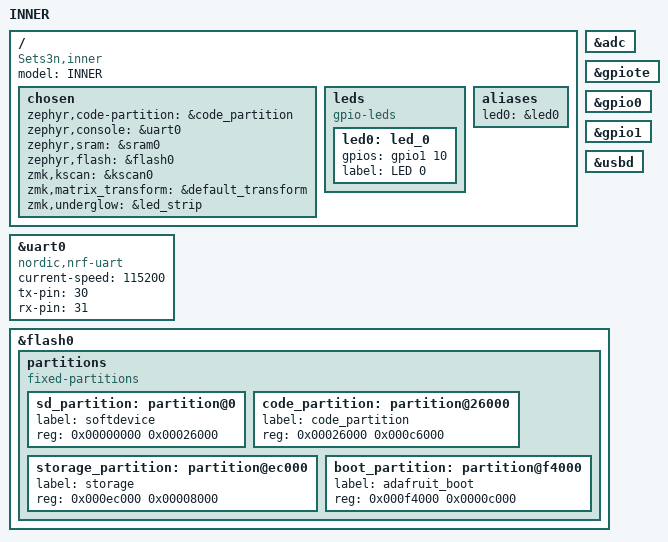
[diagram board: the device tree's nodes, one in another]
/*
 * Copyright (c) 2022 The ZMK Contributors
 *
 * SPDX-License-Identifier: MIT
 */

#include <nordic/nrf52840_qiaa.dtsi>
#include <dt-bindings/zmk/matrix_transform.h>

/ {
	model = "INNER";
	compatible = "Sets3n,inner";

	chosen {
		zephyr,code-partition = &code_partition;
		zephyr,console = &uart0;
		zephyr,sram = &sram0;
		zephyr,flash = &flash0;
		zmk,kscan = &kscan0;
		zmk,matrix_transform = &default_transform;
		zmk,underglow = &led_strip;
	};
     leds {
             compatible = "gpio-leds";
             led0: led_0 {
                     gpios = <&gpio1 10 0>;
                     label = "LED 0";
             };
             /* ... other LEDs ... */
     };
     aliases {
             led0 = &led0; /* now you support the blinky sample! */
             /* other aliases go here */
     };

};

&adc {
	status = "okay";
};

&gpiote {
	status = "okay";
};

&gpio0 {
	status = "okay";
};

&gpio1 {
	status = "okay";
};

//&spi1 {
//  compatible = "nordic,nrf-spim";
//  status = "okay";
//};

&usbd {
	status = "okay";
};


&uart0 {
    compatible = "nordic,nrf-uart";
    current-speed = <115200>;
    status = "okay";
    tx-pin = <30>;
    rx-pin = <31>;
};

&flash0 {
	/*
	 * For more information, see:
	 * http://docs.zephyrproject.org/latest/devices/dts/flash_partitions.html
	 */
	partitions {
		compatible = "fixed-partitions";
		#address-cells = <1>;
		#size-cells = <1>;

		sd_partition: partition@0 {
			label = "softdevice";
			reg = <0x00000000 0x00026000>;
		};
		code_partition: partition@26000 {
			label = "code_partition";
			reg = <0x00026000 0x000c6000>;
		};

		/*
		 * The flash starting at 0x000ec000 and ending at
		 * 0x000f3fff is reserved for use by the application.
		 */

		/*
		 * Storage partition will be used by FCB/LittleFS/NVS
		 * if enabled.
		 */
		storage_partition: partition@ec000 {
			label = "storage";
			reg = <0x000ec000 0x00008000>;
		};

		boot_partition: partition@f4000 {
			label = "adafruit_boot";
			reg = <0x000f4000 0x0000c000>;
		};
	};
};
